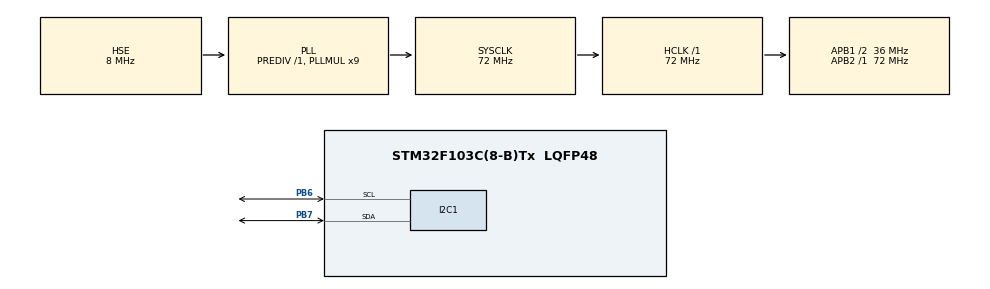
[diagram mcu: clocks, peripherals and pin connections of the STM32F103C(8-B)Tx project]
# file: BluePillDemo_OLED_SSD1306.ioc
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I2C1.I2C_Mode=I2C_Fast
Mcu.Family=STM32F1
Mcu.Name=STM32F103C(8-B)Tx
Mcu.Package=LQFP48
NVIC.PriorityGroup=NVIC_PRIORITYGROUP_4
PA13.Mode=Serial_Wire
PA13.Signal=SYS_JTMS-SWDIO
PA14.Mode=Serial_Wire
PA14.Signal=SYS_JTCK-SWCLK
PB6.Mode=I2C
PB6.Signal=I2C1_SCL
PB7.Mode=I2C
PB7.Signal=I2C1_SDA
PC14-OSC32_IN.Mode=LSE-External-Oscillator
PC14-OSC32_IN.Signal=RCC_OSC32_IN
PC15-OSC32_OUT.Mode=LSE-External-Oscillator
PC15-OSC32_OUT.Signal=RCC_OSC32_OUT
PD0-OSC_IN.Mode=HSE-External-Oscillator
PD0-OSC_IN.Signal=RCC_OSC_IN
PD1-OSC_OUT.Mode=HSE-External-Oscillator
PD1-OSC_OUT.Signal=RCC_OSC_OUT
ProjectManager.HeapSize=0x200
ProjectManager.StackSize=0x400
ProjectManager.TargetToolchain=STM32CubeIDE
RCC.AHBFreq_Value=72000000
RCC.APB1CLKDivider=RCC_HCLK_DIV2
RCC.APB1Freq_Value=36000000
RCC.APB1TimFreq_Value=72000000
RCC.APB2Freq_Value=72000000
RCC.APB2TimFreq_Value=72000000
RCC.HCLKFreq_Value=72000000
RCC.PLLMUL=RCC_PLL_MUL9
RCC.PLLSourceVirtual=RCC_PLLSOURCE_HSE
RCC.SYSCLKFreq_VALUE=72000000
RCC.SYSCLKSource=RCC_SYSCLKSOURCE_PLLCLK
RCC.USBFreq_Value=72000000
board=custom

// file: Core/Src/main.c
/* USER CODE BEGIN Header */
/**
  ******************************************************************************
  * @file           : main.c
  * @brief          : Main program body
  ******************************************************************************
  * @attention
  *
  * <h2><center>&copy; Copyright (c) 2019 STMicroelectronics.
  * All rights reserved.</center></h2>
  *
  * This software component is licensed by ST under BSD 3-Clause license,
  * the "License"; You may not use this file except in compliance with the
  * License. You may obtain a copy of the License at:
  *                        opensource.org/licenses/BSD-3-Clause
  *
  ******************************************************************************
  */
/* USER CODE END Header */

#include "main.h"

/* USER CODE BEGIN Includes */
#include <string.h>
#include <stdio.h>
#include "graphics.h"
#include "pressure_sensor.h"
#include "rotary.h"
/* USER CODE END Includes */

I2C_HandleTypeDef hi2c1;

/* USER CODE BEGIN PV */
extern const unsigned char pic[];
const int16_t triangleCornersXOrig[3] = {-5, 0, 5};
const int16_t triangleCornersYOrig[3] = {5, -5, 5};

/* USER CODE END PV */

void SystemClock_Config(void);
static void MX_GPIO_Init(void);
static void MX_I2C1_Init(void);

int _write(int file, char *ptr, int len)
{
  /* Implement your write code here, this is used by puts and printf for example */
  int i=0;
  for(i=0 ; i<len ; i++)
    ITM_SendChar((*ptr++));
  return len;
}

int main(void)
{
  /* USER CODE BEGIN 1 */
  int16_t triangleCornersX[3] = {-5, 0, 5};
  int16_t triangleCornersY[3] = {5, -5, 5};
  uint8_t i = 0U;

  /* USER CODE END 1 */

  /* MCU Configuration--------------------------------------------------------*/

  /* Reset of all peripherals, Initializes the Flash interface and the Systick. */
  HAL_Init();

  /* Configure the system clock */
  SystemClock_Config();

  /* Initialize all configured peripherals */
  MX_GPIO_Init();
  MX_I2C1_Init();
  /* USER CODE BEGIN 2 */
  pressure_sensor_init(&hi2c1);
  GraphicsInit();
  init_rotary_encoder();

  /* USER CODE END 2 */

  /* Infinite loop */
  /* USER CODE BEGIN WHILE */
  while (1)
  {
	  int cnt=0;
	  char szoveg[20];

	  GraphicsClear(true);
	  GraphicsUpdateDisplay();
	  HAL_Delay(200UL);

	  GraphicsClear(false);
	  GraphicsUpdateDisplay();
	  HAL_Delay(200UL);

	  pressure_sensor_start_measurement();
	  HAL_Delay(500U);

	  float pressure_mb;
	  float temp_c;

	  while(1){
		  printf("pos:%d\n",(TIM2->CNT));
	  }

	  while(1){

		  cnt++;
		  GraphicsClear(false);
		  GraphicsUpdateDisplay();
		  //HAL_Delay(200UL);
		  pressure_sensor_get_measurement(&pressure_mb, &temp_c);
		  int temp=temp_c;
		  uint32_t press = pressure_mb*100;
		  sprintf(szoveg,"T=%d 'C",temp);
		  pressure_sensor_start_measurement();
		  GraphicsStandardString(20, 10, szoveg, true);
		  sprintf(szoveg,"P=%d Pa",press);
		  GraphicsStandardString(20, 20, szoveg, true);
		  sprintf(szoveg,"N=%d",((TIM2->CNT)>>2));
		  GraphicsStandardString(20, 30, szoveg, true);

		  GraphicsUpdateDisplay();
		  HAL_Delay(500UL);
	  }
    /* USER CODE END WHILE */

    /* USER CODE BEGIN 3 */
	i++;
	if (i == 5U)
	{
		memcpy(triangleCornersX, triangleCornersXOrig, sizeof(triangleCornersX));
		memcpy(triangleCornersY, triangleCornersYOrig, sizeof(triangleCornersY));
		i = 0U;
	}

	GraphicsClear(true);
	GraphicsUpdateDisplay();
	HAL_Delay(200UL);

	GraphicsClear(false);
	GraphicsUpdateDisplay();
	HAL_Delay(200UL);

	GraphicsVline(10, 20, 100, true);
	GraphicsUpdateDisplay();
	GraphicsHline(0U, SSD1306_OLED_WIDTH, 50, true);
	GraphicsUpdateDisplay();
	GraphicsRectangle(15, 10, 20, 18, true);
	GraphicsUpdateDisplay();
	GraphicsStandardString(20, 30, "Freddy", true);
	GraphicsUpdateDisplay();
	GraphicsStandardStringVert(60, 20, "Freddy", true);
	GraphicsUpdateDisplay();
	HAL_Delay(500UL);

	GraphicsClear(false);
	GraphicsLargeString(10, 10, "Freddy", true);
	GraphicsUpdateDisplay();
	GraphicsLargeStringVert(100, 0, "Freddy", true);
	GraphicsUpdateDisplay();
	HAL_Delay(500UL);

	GraphicsClear(false);
	GraphicsLine(0, 0, 127, 63, true);
	GraphicsUpdateDisplay();
	GraphicsLine(0, 63, 127, 0, true);
	GraphicsUpdateDisplay();
	GraphicsCircle(63, 32, 22, true);
	GraphicsUpdateDisplay();
	HAL_Delay(500UL);

	GraphicsClear(false);
	GraphicsMonochromeBitmap(0, 0, 128, 64, pic);
	GraphicsUpdateDisplay();
	HAL_Delay(500UL);

	GraphicsClear(false);
	GraphicsFilledCircle(64, 32, 30, true);
	GraphicsUpdateDisplay();
	HAL_Delay(500UL);

	GraphicsClear(false);
	GraphicsScaleShape(3U, triangleCornersX, triangleCornersY, 15, 13);
	GraphicsRotateShape(3U, triangleCornersX, triangleCornersY, 45);
	GraphicsDrawShape(3U, triangleCornersX, triangleCornersY, 42, 32, true);
	GraphicsDrawFilledShape(3U, triangleCornersX, triangleCornersY, 84, 32, true);
	GraphicsUpdateDisplay();
	HAL_Delay(500UL);

	GraphicsClear(false);
	GraphicsArc(42, 32, 15, 45, 270, true);
	GraphicsSegment(84, 32, 15, -90, 179, true);
	GraphicsUpdateDisplay();
	HAL_Delay(500UL);

	GraphicsClear(false);
	GraphicsFilledSegment(84, 32, 15, -90, 179, 20U, true);
	GraphicsUpdateDisplay();
	HAL_Delay(500UL);

	GraphicsClear(false);
	GraphicsRoundedRectangle(20, 10, 100U, 50U, 15, true);
	GraphicsUpdateDisplay();
    HAL_Delay(500UL);
  }
  /* USER CODE END 3 */
}

void SystemClock_Config(void)
{
  RCC_OscInitTypeDef RCC_OscInitStruct = {0};
  RCC_ClkInitTypeDef RCC_ClkInitStruct = {0};

  /** Initializes the CPU, AHB and APB busses clocks
  */
  RCC_OscInitStruct.OscillatorType = RCC_OSCILLATORTYPE_HSE;
  RCC_OscInitStruct.HSEState = RCC_HSE_ON;
  RCC_OscInitStruct.HSEPredivValue = RCC_HSE_PREDIV_DIV1;
  RCC_OscInitStruct.HSIState = RCC_HSI_ON;
  RCC_OscInitStruct.PLL.PLLState = RCC_PLL_ON;
  RCC_OscInitStruct.PLL.PLLSource = RCC_PLLSOURCE_HSE;
  RCC_OscInitStruct.PLL.PLLMUL = RCC_PLL_MUL9;
  if (HAL_RCC_OscConfig(&RCC_OscInitStruct) != HAL_OK)
  {
    Error_Handler();
  }
  /** Initializes the CPU, AHB and APB busses clocks
  */
  RCC_ClkInitStruct.ClockType = RCC_CLOCKTYPE_HCLK|RCC_CLOCKTYPE_SYSCLK
                              |RCC_CLOCKTYPE_PCLK1|RCC_CLOCKTYPE_PCLK2;
  RCC_ClkInitStruct.SYSCLKSource = RCC_SYSCLKSOURCE_PLLCLK;
  RCC_ClkInitStruct.AHBCLKDivider = RCC_SYSCLK_DIV1;
  RCC_ClkInitStruct.APB1CLKDivider = RCC_HCLK_DIV2;
  RCC_ClkInitStruct.APB2CLKDivider = RCC_HCLK_DIV1;

  if (HAL_RCC_ClockConfig(&RCC_ClkInitStruct, FLASH_LATENCY_2) != HAL_OK)
  {
    Error_Handler();
  }
}

static void MX_I2C1_Init(void)
{

  hi2c1.Instance = I2C1;
  hi2c1.Init.ClockSpeed = 400000;
  hi2c1.Init.DutyCycle = I2C_DUTYCYCLE_2;
  hi2c1.Init.OwnAddress1 = 0;
  hi2c1.Init.AddressingMode = I2C_ADDRESSINGMODE_7BIT;
  hi2c1.Init.DualAddressMode = I2C_DUALADDRESS_DISABLE;
  hi2c1.Init.OwnAddress2 = 0;
  hi2c1.Init.GeneralCallMode = I2C_GENERALCALL_DISABLE;
  hi2c1.Init.NoStretchMode = I2C_NOSTRETCH_DISABLE;
  if (HAL_I2C_Init(&hi2c1) != HAL_OK)
  {
    Error_Handler();
  }

}

static void MX_GPIO_Init(void)
{

  /* GPIO Ports Clock Enable */
  __HAL_RCC_GPIOC_CLK_ENABLE();
  __HAL_RCC_GPIOD_CLK_ENABLE();
  __HAL_RCC_GPIOA_CLK_ENABLE();
  __HAL_RCC_GPIOB_CLK_ENABLE();

}

void Error_Handler(void)
{
}

/************************ (C) COPYRIGHT STMicroelectronics *****END OF FILE****/
